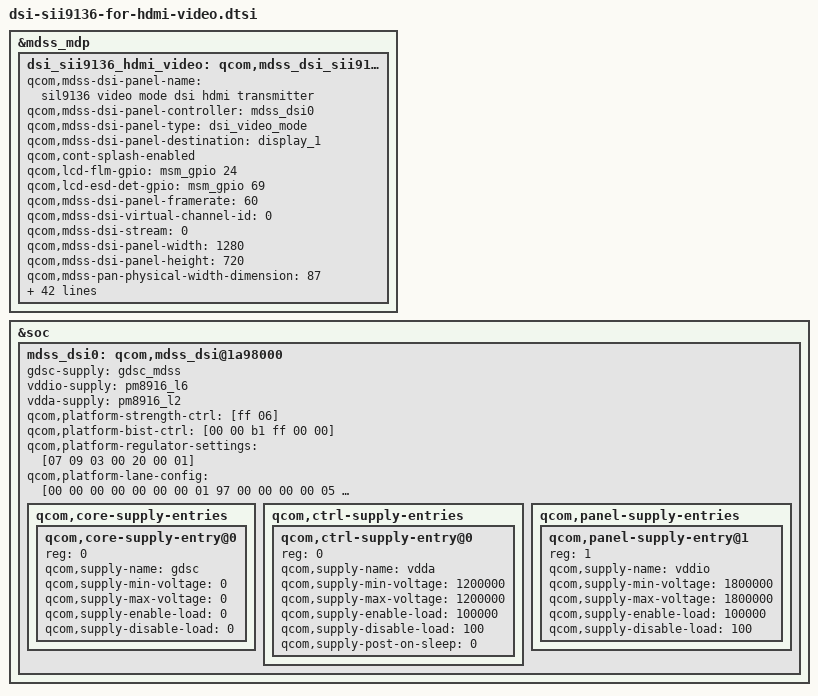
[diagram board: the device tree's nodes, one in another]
/* Copyright (c) 2013-14, Samsung Electronics Corporation. All rights reserved.
 *
 * This program is free software; you can redistribute it and/or modify
 * it under the terms of the GNU General Public License version 2 and
 * only version 2 as published by the Free Software Foundation.
 *
 * This program is distributed in the hope that it will be useful,
 * but WITHOUT ANY WARRANTY; without even the implied warranty of
 * MERCHANTABILITY or FITNESS FOR A PARTICULAR PURPOSE.  See the
 * GNU General Public License for more details.
 */

/*---------------------------------------------------------------------------
 * This file is autogenerated file using gcdb parser. Please do not edit it.
 * Update input XML file to add a new entry or update variable in this file
 * VERSION = "1.0"
 *---------------------------------------------------------------------------

 */
&mdss_mdp {
	dsi_sii9136_hdmi_video: qcom,mdss_dsi_sii9136_video {
		qcom,mdss-dsi-panel-name = "sil9136 video mode dsi hdmi transmitter";
		qcom,mdss-dsi-panel-controller = <&mdss_dsi0>;
		qcom,mdss-dsi-panel-type = "dsi_video_mode";
		qcom,mdss-dsi-panel-destination = "display_1";
		qcom,cont-splash-enabled;
		qcom,lcd-flm-gpio = <&msm_gpio 24 0>;
		qcom,lcd-esd-det-gpio = <&msm_gpio 69 0>;
		qcom,mdss-dsi-panel-framerate = <60>;
		qcom,mdss-dsi-virtual-channel-id = <0>;
		qcom,mdss-dsi-stream = <0>;
		qcom,mdss-dsi-panel-width = <1280>;
		qcom,mdss-dsi-panel-height = <720>;
		qcom,mdss-pan-physical-width-dimension = <87>; /* <Width> real size of panel in mm */
		qcom,mdss-pan-physical-height-dimension = <52>; /*<Height> real size of panel in mm */
		qcom,mdss-dsi-lp11-init;
		qcom,mdss-dsi-init-delay-us = <100>;
		qcom,mdss-dsi-h-front-porch = <132>;
		qcom,mdss-dsi-h-back-porch = <180>;
		qcom,mdss-dsi-h-pulse-width = <60>;
		qcom,mdss-dsi-h-sync-skew = <0>;
		qcom,mdss-dsi-v-back-porch = <20>;
		qcom,mdss-dsi-v-front-porch = <5>;
		qcom,mdss-dsi-v-pulse-width = <4>;
		qcom,mdss-dsi-h-left-border = <0>;
		qcom,mdss-dsi-h-right-border = <0>;
		qcom,mdss-dsi-v-top-border = <0>;
		qcom,mdss-dsi-v-bottom-border = <0>;
		qcom,mdss-dsi-bpp = <24>;
		qcom,mdss-dsi-color-order = <0>;
		qcom,mdss-dsi-underflow-color = <0xff>;
		qcom,mdss-dsi-border-color = <0>;
		qcom,mdss-dsi-dma-trigger = "trigger_sw";
		qcom,mdss-dsi-mdp-trigger = "none";
		qcom,mdss-dsi-bl-min-level = <1>;
		qcom,mdss-dsi-bl-max-level = <255>;
		qcom,mdss-dsi-bl-pmic-control-type = "bl_ctrl_wled";
		qcom,mdss-dsi-lane-0-state;
		qcom,mdss-dsi-lane-1-state;
		qcom,mdss-dsi-lane-2-state;
		qcom,mdss-dsi-lane-3-state;
		qcom,mdss-dsi-hfp-power-mode;
		qcom,mdss-dsi-hsa-power-mode;
		qcom,mdss-dsi-hbp-power-mode;
		qcom,mdss-dsi-bllp-eof-power-mode;
		qcom,mdss-dsi-bllp-power-mode;
		qcom,mdss-dsi-traffic-mode = "non_burst_sync_pulse";
		qcom,mdss-force-clk-lane-hs = <1>;
		qcom,mdss-dsi-reset-sequence = <1 20>, <0 1>, <1 20>;
		qcom,mdss-dsi-h-sync-pulse = <0>;
		qcom,mdss-dsi-panel-timings = [7E 20 12 00 40 44 16 22 20 03 04 00];
		qcom,mdss-dsi-t-clk-pre = <0x1b>;
		qcom,mdss-dsi-t-clk-post = <0x04>;
	};
};
&soc {
	mdss_dsi0: qcom,mdss_dsi@1a98000 {
		gdsc-supply = <&gdsc_mdss>;
		vddio-supply = <&pm8916_l6>;
		vdda-supply = <&pm8916_l2>;
		qcom,platform-strength-ctrl = [ff 06];
		qcom,platform-bist-ctrl = [00 00 b1 ff 00 00];
		qcom,platform-regulator-settings = [07 09 03 00 20 00 01];
		qcom,platform-lane-config = [00 00 00 00 00 00 00 01 97
			00 00 00 00 05 00 00 01 97
			00 00 00 00 0a 00 00 01 97
			00 00 00 00 0f 00 00 01 97
			00 c0 00 00 00 00 00 01 bb];
		qcom,core-supply-entries {
			#address-cells = <1>;
			#size-cells = <0>;

			qcom,core-supply-entry@0 {
				reg = <0>;
				qcom,supply-name = "gdsc";
				qcom,supply-min-voltage = <0>;
				qcom,supply-max-voltage = <0>;
				qcom,supply-enable-load = <0>;
				qcom,supply-disable-load = <0>;
			};
		};
		qcom,ctrl-supply-entries {
			#address-cells = <1>;
			#size-cells = <0>;

			qcom,ctrl-supply-entry@0 {
				reg = <0>;
				qcom,supply-name = "vdda";
				qcom,supply-min-voltage = <1200000>;
				qcom,supply-max-voltage = <1200000>;
				qcom,supply-enable-load = <100000>;
				qcom,supply-disable-load = <100>;
				qcom,supply-post-on-sleep = <0>;
			};
		};
		qcom,panel-supply-entries {
			#address-cells = <1>;
			#size-cells = <0>;

			qcom,panel-supply-entry@1 {
				reg = <1>;
				qcom,supply-name = "vddio";
				qcom,supply-min-voltage = <1800000>;
				qcom,supply-max-voltage = <1800000>;
				qcom,supply-enable-load = <100000>;
				qcom,supply-disable-load = <100>;
			};
		};
	};
};
